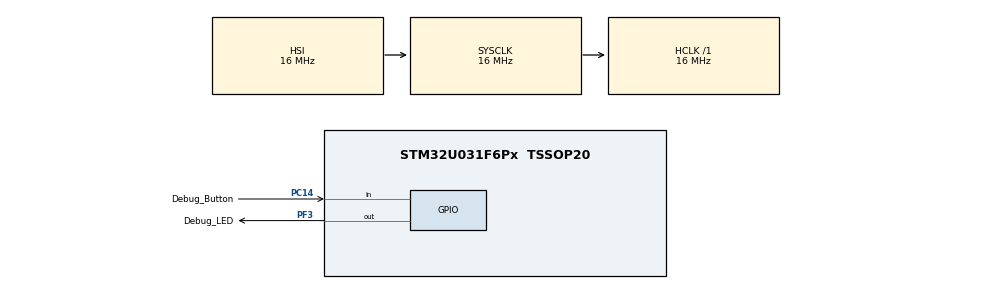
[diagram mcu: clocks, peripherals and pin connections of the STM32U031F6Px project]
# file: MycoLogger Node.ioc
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Mcu.Family=STM32U0
Mcu.Name=STM32U031F6Px
Mcu.Package=TSSOP20
NVIC.PriorityGroup=NVIC_PRIORITYGROUP_2
PA14\ (SWCLK)__PB4__PB5__PB6.StandardMode=true
PA1__PA2.StandardMode=true
PA3__PA4.StandardMode=true
PA5__PA6.StandardMode=true
PA7__PB0.StandardMode=true
PB8__PB9.StandardMode=true
PC14-OSC32_IN.GPIO_Label=Debug_Button
PC14-OSC32_IN.GPIO_PuPd=GPIO_PULLUP
PC14-OSC32_IN.Signal=GPIO_Input
PF3-BOOT0\ (BOOT0).GPIO_Label=Debug_LED
PF3-BOOT0\ (BOOT0).Signal=GPIO_Output
ProjectManager.HeapSize=0x200
ProjectManager.StackSize=0x400
ProjectManager.TargetToolchain=STM32CubeIDE
RCC.AHBFreq_Value=16000000
RCC.CortexFreq_Value=16000000
RCC.HCLKFreq_Value=16000000
RCC.HSE_VALUE=4000000
RCC.HSI48_VALUE=48000000
RCC.HSI_VALUE=16000000
RCC.LSE_VALUE=32768
RCC.MSI_VALUE=4000000
RCC.SYSCLKFreq_VALUE=16000000
RCC.VCOOutputFreq_Value=64000000
VP_PWR_VS_SECSignals.Mode=Security/Privilege
board=custom

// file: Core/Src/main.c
/* USER CODE BEGIN Header */
/**
  ******************************************************************************
  * @file           : main.c
  * @brief          : Main program body
  ******************************************************************************
  * @attention
  *
  * Copyright (c) 2026 STMicroelectronics.
  * All rights reserved.
  *
  * This software is licensed under terms that can be found in the LICENSE file
  * in the root directory of this software component.
  * If no LICENSE file comes with this software, it is provided AS-IS.
  *
  ******************************************************************************
  */
/* USER CODE END Header */
#include "main.h"

/* USER CODE BEGIN Includes */

#include "sx1262_tx.h"
#include "scd41.h"
#include "node_config.h"
#include "battery_adc.h"

/* USER CODE END Includes */

/* USER CODE BEGIN PD */

#define BOOT_BLINK_TIME_MS          100U
#define DEFAULT_REPORT_INTERVAL_MS 60000U
#define DEFAULT_DOWNLINK_WINDOW_MS  1500U
#define BUTTON_DEBOUNCE_TIME_MS       30U
#define NODE_ID_BLINK_ON_TIME_MS      90U
#define NODE_ID_BLINK_OFF_TIME_MS    110U
#define CONFIG_BLINK_COUNT              6U
#define CONFIG_BLINK_ON_TIME_MS        45U
#define CONFIG_BLINK_OFF_TIME_MS       55U
#define NETWORK_CHECK_DURATION_MS    30000U
#define NETWORK_BLINK_ON_TIME_MS       100U
#define NETWORK_BLINK_OFF_TIME_MS      100U
#define NETWORK_BLINK_PAUSE_MS        1000U
#define NETWORK_FAIL_BLINK_COUNT         5U
#define RADIO_RETRY_INTERVAL_MS     5000U
#define RADIO_ERROR_PATTERN_MS      2000U
#define SENSOR_PACKET_SIZE            51U
#define CONFIG_PACKET_SIZE            26U
#define CONFIG_ACK_PACKET_SIZE        27U
#define TEST_PACKET_VERSION            1U
#define TEST_PACKET_SENSOR_READING     2U
#define TEST_PACKET_LINK_CHECK         3U
#define TEST_PACKET_SET_CONFIG      0x80U
#define TEST_PACKET_CONFIG_ACK      0x81U
#define TEST_PACKET_LINK_ACK        0x82U
#define LINK_ACK_PACKET_SIZE           14U
#define LINK_CHECK_PACKET_SIZE         14U
#define DEFAULT_NODE_ID                0U
#define FIRMWARE_VERSION_MAJOR         0U
#define FIRMWARE_VERSION_MINOR         8U
#define FIRMWARE_VERSION_PATCH         6U
#define IWDG_KEY_ENABLE             0xCCCCU
#define IWDG_KEY_WRITE_ACCESS       0x5555U
#define IWDG_KEY_REFRESH            0xAAAAU
#define IWDG_PRESCALER_DIV64              4U
#define IWDG_RELOAD_8_SECONDS          3999U
#define IWDG_WINDOW_DISABLED           4095U
#define IWDG_UPDATE_TIMEOUT_MS           10U
#define IWDG_REFRESH_INTERVAL_MS       1000U
#define LPTIM_LSI_HZ                  32000U
#define LPTIM_STOP_PRESCALER             5U /* /32, therefore 1 kHz. */
#define LPTIM_TICKS_PER_SECOND        1000U
#define LPTIM_MAX_SLEEP_SECONDS         65U
#define RESET_CAUSE_FLAGS (RCC_CSR_OBLRSTF | RCC_CSR_PINRSTF | \
                           RCC_CSR_PWRRSTF | RCC_CSR_SFTRSTF | \
                           RCC_CSR_IWDGRSTF | RCC_CSR_WWDGRSTF | \
                           RCC_CSR_LPWRRSTF)

/* USER CODE END PD */

/* USER CODE BEGIN PV */

/* Retained for ST-LINK inspection and future over-the-air diagnostics. */
volatile uint32_t g_boot_reset_flags = 0U;
volatile bool g_stop_timer_wake = false;
volatile bool g_debug_button_wake = false;

/* USER CODE END PV */

void SystemClock_Config(void);
static void MX_GPIO_Init(void);

/* USER CODE BEGIN 0 */

static void BlinkDebugLedAtBoot(void)
{
  for (uint8_t blink = 0; blink < 3U; blink++)
  {
    HAL_GPIO_WritePin(Debug_LED_GPIO_Port, Debug_LED_Pin, GPIO_PIN_SET);
    HAL_Delay(BOOT_BLINK_TIME_MS);

    HAL_GPIO_WritePin(Debug_LED_GPIO_Port, Debug_LED_Pin, GPIO_PIN_RESET);
    HAL_Delay(BOOT_BLINK_TIME_MS);
  }
}

static bool IndependentWatchdog_Start(void)
{
  uint32_t started;

  /* Keep source-level debugging usable; deployed operation is unaffected. */
  DBGMCU->APBFZ1 |= DBGMCU_APBFZ1_DBG_IWDG_STOP;

  /* Start the LSI-clocked watchdog, then program an approximately 8 s period. */
  IWDG->KR = IWDG_KEY_ENABLE;
  IWDG->KR = IWDG_KEY_WRITE_ACCESS;
  IWDG->PR = IWDG_PRESCALER_DIV64;
  IWDG->RLR = IWDG_RELOAD_8_SECONDS;
  IWDG->WINR = IWDG_WINDOW_DISABLED;

  started = HAL_GetTick();
  while ((IWDG->SR & (IWDG_SR_PVU | IWDG_SR_RVU | IWDG_SR_WVU)) != 0U)
  {
    if ((HAL_GetTick() - started) >= IWDG_UPDATE_TIMEOUT_MS)
    {
      return false;
    }
  }

  IWDG->KR = IWDG_KEY_REFRESH;
  return true;
}

static bool Stop2_IsWatchdogSafe(void)
{
  /* A zero IWDG_STOP option freezes the watchdog during Stop mode. */
  return (FLASH->OPTR & FLASH_OPTR_IWDG_STOP) == 0U;
}

static bool Stop2_Init(void)
{
  uint32_t started = HAL_GetTick();

  __HAL_RCC_LSI_ENABLE();
  while ((RCC->CSR & RCC_CSR_LSIRDY) == 0U)
  {
    if ((HAL_GetTick() - started) >= IWDG_UPDATE_TIMEOUT_MS)
    {
      return false;
    }
  }

  __HAL_RCC_LPTIM1_CLK_ENABLE();
  __HAL_RCC_LPTIM1_CONFIG(RCC_LPTIM1CLKSOURCE_LSI);
  LPTIM1->CR = 0U;
  LPTIM1->CFGR = (LPTIM_STOP_PRESCALER << LPTIM_CFGR_PRESC_Pos);
  LPTIM1->ICR = 0x7FU;
  LPTIM1->DIER = LPTIM_DIER_ARRMIE;
  HAL_NVIC_SetPriority(TIM6_DAC_LPTIM1_IRQn, 2U, 0U);
  HAL_NVIC_EnableIRQ(TIM6_DAC_LPTIM1_IRQn);
  return true;
}

static void Stop2_ArmTimer(uint32_t sleep_seconds)
{
  uint32_t ticks = sleep_seconds * LPTIM_TICKS_PER_SECOND;

  if (ticks == 0U)
  {
    ticks = 1U;
  }
  if (ticks > UINT16_MAX)
  {
    ticks = UINT16_MAX;
  }

  LPTIM1->CR = 0U;
  LPTIM1->ICR = 0x7FU;
  LPTIM1->CR = LPTIM_CR_ENABLE;
  LPTIM1->ARR = ticks - 1U;
  while ((LPTIM1->ISR & LPTIM_ISR_ARROK) == 0U)
  {
  }
  LPTIM1->ICR = LPTIM_ICR_ARROKCF;
  LPTIM1->CR |= LPTIM_CR_SNGSTRT;
}

static void Stop2_Enter(uint32_t sleep_seconds)
{
  Stop2_ArmTimer(sleep_seconds);
  g_stop_timer_wake = false;
  EXTI->RPR1 = EXTI_RPR1_RPIF14;
  EXTI->FPR1 = EXTI_FPR1_FPIF14;
  HAL_SuspendTick();
  MODIFY_REG(PWR->CR1, PWR_CR1_LPMS, PWR_CR1_LPMS_1);
  SET_BIT(SCB->SCR, SCB_SCR_SLEEPDEEP_Msk);
  __DSB();
  __ISB();
  __WFI();
  CLEAR_BIT(SCB->SCR, SCB_SCR_SLEEPDEEP_Msk);
  /* A button wake can arrive before the timer. Do not let the old one-shot
     expire while a sensor/radio state machine is now running. */
  LPTIM1->CR = 0U;
  SystemClock_Config();
  HAL_ResumeTick();
}

void LPTIM1_StopWake_IRQHandler(void)
{
  if ((LPTIM1->ISR & LPTIM_ISR_ARRM) != 0U)
  {
    LPTIM1->ICR = LPTIM_ICR_ARRMCF;
    g_stop_timer_wake = true;
  }
}

void DebugButton_StopWake_IRQHandler(void)
{
  if ((EXTI->FPR1 & EXTI_FPR1_FPIF14) != 0U)
  {
    EXTI->FPR1 = EXTI_FPR1_FPIF14;
    g_debug_button_wake = true;
  }
}

static void IndependentWatchdog_Refresh(void)
{
  IWDG->KR = IWDG_KEY_REFRESH;
}

static void IncrementFailureCounter(uint16_t *counter)
{
  if ((counter != NULL) && (*counter != UINT16_MAX))
  {
    (*counter)++;
  }
}

static bool NetworkCheckIsStillAllowed(uint32_t now,
                                       uint32_t started)
{
  return (now - started) < NETWORK_CHECK_DURATION_MS;
}

static bool NetworkIndicatorIsOn(uint32_t now, uint32_t started)
{
  const uint32_t cycle = NETWORK_BLINK_ON_TIME_MS +
                         NETWORK_BLINK_OFF_TIME_MS +
                         NETWORK_BLINK_ON_TIME_MS +
                         NETWORK_BLINK_PAUSE_MS;
  uint32_t phase = (now - started) % cycle;

  return (phase < NETWORK_BLINK_ON_TIME_MS) ||
         ((phase >= (NETWORK_BLINK_ON_TIME_MS + NETWORK_BLINK_OFF_TIME_MS)) &&
          (phase < (NETWORK_BLINK_ON_TIME_MS + NETWORK_BLINK_OFF_TIME_MS +
                    NETWORK_BLINK_ON_TIME_MS)));
}

static void WriteUint32BigEndian(uint8_t *destination, uint32_t value)
{
  destination[0] = (uint8_t)(value >> 24);
  destination[1] = (uint8_t)(value >> 16);
  destination[2] = (uint8_t)(value >> 8);
  destination[3] = (uint8_t)value;
}

static void WriteUint16BigEndian(uint8_t *destination, uint16_t value)
{
  destination[0] = (uint8_t)(value >> 8);
  destination[1] = (uint8_t)value;
}

static uint32_t ReadUint32BigEndian(const uint8_t *source)
{
  return ((uint32_t)source[0] << 24) |
         ((uint32_t)source[1] << 16) |
         ((uint32_t)source[2] << 8) |
         (uint32_t)source[3];
}

static void BuildSensorPacket(uint8_t *packet,
                              const MycoNodeConfig *config,
                              uint32_t sequence,
                              bool buttonPressed,
                              bool networkCheckRequested,
                              bool sensorValid,
                              bool batteryValid,
                              uint16_t batteryMillivolts,
                              const SCD41Measurement *measurement,
                              SCD41Error sensorError,
                              uint16_t sensorFailureCount,
                              uint16_t radioFailureCount)
{
  packet[0] = 'M';
  packet[1] = 'Y';
  packet[2] = 'C';
  packet[3] = 'O';
  packet[4] = TEST_PACKET_VERSION;
  packet[5] = TEST_PACKET_SENSOR_READING;
  WriteUint32BigEndian(&packet[6], config->node_id);
  WriteUint32BigEndian(&packet[10], sequence);
  WriteUint32BigEndian(&packet[14], HAL_GetTick() / 1000U);
  packet[18] = (buttonPressed ? 0x01U : 0x00U) |
               (sensorValid ? 0x02U : 0x00U) |
               (batteryValid ? 0x04U : 0x00U) |
               (networkCheckRequested ? 0x08U : 0x00U);
  WriteUint16BigEndian(&packet[19],
                       sensorValid ? measurement->co2_ppm : 0U);
  WriteUint16BigEndian(
      &packet[21],
      sensorValid ? (uint16_t)measurement->temperature_centi_c : 0U);
  WriteUint16BigEndian(
      &packet[23],
      sensorValid ? measurement->humidity_centi_percent : 0U);
  packet[25] = (uint8_t)sensorError;
  WriteUint32BigEndian(&packet[26], config->revision);
  WriteUint32BigEndian(&packet[30], config->report_interval_ms / 1000U);
  WriteUint16BigEndian(&packet[34],
                       batteryValid ? batteryMillivolts : 0U);
  /* A compact semantic version is included in every measurement. Repeating
     three bytes makes version discovery self-healing after server restarts or
     database restores without materially affecting LoRa airtime. */
  packet[36] = FIRMWARE_VERSION_MAJOR;
  packet[37] = FIRMWARE_VERSION_MINOR;
  packet[38] = FIRMWARE_VERSION_PATCH;
  /* These counters reset at boot and describe recoverable failures observed
     since this boot.  The reset flags identify why the current boot began. */
  WriteUint32BigEndian(&packet[39], g_boot_reset_flags);
  WriteUint16BigEndian(&packet[43], sensorFailureCount);
  WriteUint16BigEndian(&packet[45], radioFailureCount);
  WriteUint32BigEndian(&packet[47], config->downlink_window_ms);
}

static bool ApplyConfigPacket(const SX1262RxPacket *packet,
                              MycoNodeConfig *config,
                              uint32_t *transactionId,
                              uint8_t *status)
{
  uint32_t targetNodeId;
  uint32_t revision;
  uint32_t reportIntervalS;

  if ((packet == NULL) || (config == NULL) ||
      (transactionId == NULL) || (status == NULL) ||
      (packet->length != CONFIG_PACKET_SIZE) ||
      (packet->payload[0] != 'M') ||
      (packet->payload[1] != 'Y') ||
      (packet->payload[2] != 'C') ||
      (packet->payload[3] != 'O') ||
      (packet->payload[4] != TEST_PACKET_VERSION) ||
      (packet->payload[5] != TEST_PACKET_SET_CONFIG))
  {
    return false;
  }

  targetNodeId = ReadUint32BigEndian(&packet->payload[6]);
  *transactionId = ReadUint32BigEndian(&packet->payload[10]);
  revision = ReadUint32BigEndian(&packet->payload[14]);
  reportIntervalS = ReadUint32BigEndian(&packet->payload[18]);
  uint32_t downlinkWindowMs = ReadUint32BigEndian(&packet->payload[22]);

  return NodeConfig_Apply(config,
                          targetNodeId,
                          *transactionId,
                          revision,
                          reportIntervalS,
                          downlinkWindowMs,
                          status);
}

static void BuildConfigAckPacket(uint8_t *packet,
                                 const MycoNodeConfig *config,
                                 uint32_t transactionId,
                                 uint8_t status)
{
  packet[0] = 'M';
  packet[1] = 'Y';
  packet[2] = 'C';
  packet[3] = 'O';
  packet[4] = TEST_PACKET_VERSION;
  packet[5] = TEST_PACKET_CONFIG_ACK;
  WriteUint32BigEndian(&packet[6], config->node_id);
  WriteUint32BigEndian(&packet[10], transactionId);
  WriteUint32BigEndian(&packet[14], config->revision);
  packet[18] = status;
  WriteUint32BigEndian(&packet[19], config->report_interval_ms / 1000U);
  WriteUint32BigEndian(&packet[23], config->downlink_window_ms);
}

static bool IsLinkAckPacket(const SX1262RxPacket *packet,
                            const MycoNodeConfig *config,
                            uint32_t expectedSequence)
{
  return (packet != NULL) && (config != NULL) &&
         (packet->length == LINK_ACK_PACKET_SIZE) &&
         (packet->payload[0] == 'M') &&
         (packet->payload[1] == 'Y') &&
         (packet->payload[2] == 'C') &&
         (packet->payload[3] == 'O') &&
         (packet->payload[4] == TEST_PACKET_VERSION) &&
         (packet->payload[5] == TEST_PACKET_LINK_ACK) &&
         (ReadUint32BigEndian(&packet->payload[6]) == config->node_id) &&
         (ReadUint32BigEndian(&packet->payload[10]) == expectedSequence);
}

static void BuildLinkCheckPacket(uint8_t *packet,
                                 const MycoNodeConfig *config,
                                 uint32_t checkSequence)
{
  packet[0] = 'M';
  packet[1] = 'Y';
  packet[2] = 'C';
  packet[3] = 'O';
  packet[4] = TEST_PACKET_VERSION;
  packet[5] = TEST_PACKET_LINK_CHECK;
  WriteUint32BigEndian(&packet[6], config->node_id);
  WriteUint32BigEndian(&packet[10], checkSequence);
}

/* USER CODE END 0 */

int main(void)
{

  /* MCU Configuration--------------------------------------------------------*/

  /* Reset of all peripherals, Initializes the Flash interface and the Systick. */
  HAL_Init();

  /* USER CODE BEGIN Init */

  g_boot_reset_flags = RCC->CSR & RESET_CAUSE_FLAGS;
  RCC->CSR |= RCC_CSR_RMVF;

  /* USER CODE END Init */

  /* Configure the system clock */
  SystemClock_Config();

  /* Initialize all configured peripherals */
  MX_GPIO_Init();
  /* USER CODE BEGIN 2 */

  if (!IndependentWatchdog_Start())
  {
    Error_Handler();
  }

  BlinkDebugLedAtBoot();
  SX1262_TX_BusInit();
  SCD41_BusInit();
  BatteryADC_InitPin();

  MycoNodeConfig nodeConfig;
  NodeConfig_Load(&nodeConfig,
                  DEFAULT_NODE_ID,
                  DEFAULT_REPORT_INTERVAL_MS,
                  DEFAULT_DOWNLINK_WINDOW_MS);
  bool provisioningConfirmation =
      NodeConfig_ConsumeProvisioningMarker(&nodeConfig);

  /* Node zero is deliberately silent until an ST-LINK provisioner writes a
     valid identity into the reserved configuration flash page. */
  if (nodeConfig.node_id == 0U)
  {
    while (1)
    {
      for (uint32_t flash = 0U; flash < 4U; flash++)
      {
        HAL_GPIO_WritePin(Debug_LED_GPIO_Port,
                          Debug_LED_Pin,
                          GPIO_PIN_SET);
        HAL_Delay(90U);
        HAL_GPIO_WritePin(Debug_LED_GPIO_Port,
                          Debug_LED_Pin,
                          GPIO_PIN_RESET);
        HAL_Delay(110U);
      }
      IndependentWatchdog_Refresh();
      HAL_Delay(1800U);
    }
  }

  uint8_t radioStatus = 0U;
  bool radioReady =
      SX1262_TX_Init(&radioStatus) == SX1262_TX_STATUS_OK;
  bool sensorCycleFailed = false;
  uint16_t sensorFailureCount = 0U;
  uint16_t radioFailureCount = 0U;
  bool sensorMeasurementValid = false;
  bool sensorPacketPending = false;
  bool sensorTransmitActive = false;
  bool downlinkReceiveActive = false;
  bool configAckTransmitActive = false;
  bool networkLinkPacketPending = radioReady;
  bool networkLinkTransmitActive = false;
  bool networkConfirmationPending = true;
  bool networkStartupCheckActive = radioReady;
  bool stop2Ready = Stop2_IsWatchdogSafe() && Stop2_Init();
  uint32_t networkCheckSequence = 0U;
  uint32_t networkCheckStartedTick = HAL_GetTick();
  SCD41Measurement sensorMeasurement = {0};
  uint32_t lastRadioInitTick = HAL_GetTick();
  uint32_t lastSensorCycleTick = HAL_GetTick();
  uint32_t stop2ElapsedMs = 0U;
  uint32_t stop2ArmedMs = 0U;
  uint32_t ledSequenceTick = HAL_GetTick();
  uint32_t ledSequenceBlinksRemaining =
      provisioningConfirmation ? CONFIG_BLINK_COUNT : 0U;
  uint32_t ledSequenceOnTimeMs = CONFIG_BLINK_ON_TIME_MS;
  uint32_t ledSequenceOffTimeMs = CONFIG_BLINK_OFF_TIME_MS;
  bool ledSequenceActive = provisioningConfirmation;
  bool ledSequenceLedOn = provisioningConfirmation;
  uint32_t transmitSequence = 0U;
  uint8_t sensorPacket[SENSOR_PACKET_SIZE];
  uint8_t linkCheckPacket[LINK_CHECK_PACKET_SIZE];
  uint8_t configAckPacket[CONFIG_ACK_PACKET_SIZE];
  SX1262RxPacket downlinkPacket;
  uint32_t configTransactionId = 0U;
  uint8_t configStatus = 0U;
  uint16_t batteryMillivolts = 0U;
  GPIO_PinState rawButtonState =
      HAL_GPIO_ReadPin(Debug_Button_GPIO_Port, Debug_Button_Pin);
  GPIO_PinState previousRawButtonState = rawButtonState;
  GPIO_PinState debouncedButtonState = rawButtonState;
  uint32_t buttonDebounceTick = HAL_GetTick();
  uint32_t lastWatchdogRefreshTick = HAL_GetTick();

  /* Take the first sample immediately; subsequent starts are one minute apart. */
  if (SCD41_StartSingleShot() != SCD41_STATUS_OK)
  {
    sensorCycleFailed = true;
    IncrementFailureCounter(&sensorFailureCount);
    sensorPacketPending = true;
  }

  /* USER CODE END 2 */

  /* Infinite loop */
  while (1)
  {

    /* USER CODE BEGIN 3 */
    uint32_t now = HAL_GetTick();
    if (g_debug_button_wake)
    {
      g_debug_button_wake = false;
      rawButtonState = GPIO_PIN_RESET;
      previousRawButtonState = GPIO_PIN_RESET;
      buttonDebounceTick = now - BUTTON_DEBOUNCE_TIME_MS;
    }
    else
    {
      rawButtonState = HAL_GPIO_ReadPin(Debug_Button_GPIO_Port,
                                        Debug_Button_Pin);
    }
    if (rawButtonState != previousRawButtonState)
    {
      previousRawButtonState = rawButtonState;
      buttonDebounceTick = now;
    }

    if (((now - buttonDebounceTick) >= BUTTON_DEBOUNCE_TIME_MS) &&
        (rawButtonState != debouncedButtonState))
    {
      debouncedButtonState = rawButtonState;
      if (debouncedButtonState == GPIO_PIN_RESET)
      {
        /* Identify this physical transmitter without blocking sensing/radio. */
        ledSequenceBlinksRemaining = nodeConfig.node_id;
        ledSequenceOnTimeMs = NODE_ID_BLINK_ON_TIME_MS;
        ledSequenceOffTimeMs = NODE_ID_BLINK_OFF_TIME_MS;
        ledSequenceActive = ledSequenceBlinksRemaining > 0U;
        ledSequenceLedOn = ledSequenceActive;
        ledSequenceTick = now;

        if (!SCD41_IsActive())
        {
          /* A press always requests a new sensor conversion before transmit. */
          stop2ElapsedMs = 0U;
          lastSensorCycleTick = now;
          sensorMeasurementValid = false;
          if (SCD41_StartSingleShot() != SCD41_STATUS_OK)
          {
            sensorCycleFailed = true;
            IncrementFailureCounter(&sensorFailureCount);
            sensorPacketPending = true;
          }
        }
      }
    }

    bool buttonPressed = debouncedButtonState == GPIO_PIN_RESET;

    if (g_stop_timer_wake)
    {
      g_stop_timer_wake = false;
      stop2ElapsedMs += stop2ArmedMs;
      stop2ArmedMs = 0U;
    }

    if (SCD41_IsActive())
    {
      SCD41Event sensorEvent = SCD41_Poll(&sensorMeasurement);
      if (sensorEvent == SCD41_EVENT_MEASUREMENT)
      {
        sensorMeasurementValid = true;
        sensorCycleFailed = false;
        sensorPacketPending = true;
      }
      else if ((sensorEvent == SCD41_EVENT_BUS_ERROR) ||
               (sensorEvent == SCD41_EVENT_CRC_ERROR))
      {
        sensorMeasurementValid = false;
        sensorCycleFailed = true;
        IncrementFailureCounter(&sensorFailureCount);
        sensorPacketPending = true;
      }
    }
    else if (((now - lastSensorCycleTick) + stop2ElapsedMs) >=
             nodeConfig.report_interval_ms)
    {
      stop2ElapsedMs = 0U;
      HAL_GPIO_WritePin(Sensor_Power_GPIO_Port,
                        Sensor_Power_Pin,
                        GPIO_PIN_RESET);
      lastSensorCycleTick = now;
      sensorMeasurementValid = false;
      if (SCD41_StartSingleShot() != SCD41_STATUS_OK)
      {
        sensorCycleFailed = true;
        IncrementFailureCounter(&sensorFailureCount);
        sensorPacketPending = true;
      }
    }

    if (!radioReady &&
        ((now - lastRadioInitTick) >= RADIO_RETRY_INTERVAL_MS))
    {
      lastRadioInitTick = now;
      radioReady =
          SX1262_TX_Init(&radioStatus) == SX1262_TX_STATUS_OK;
      if (!radioReady)
      {
        IncrementFailureCounter(&radioFailureCount);
      }
      if (radioReady && networkConfirmationPending &&
          NetworkCheckIsStillAllowed(now, networkCheckStartedTick))
      {
        networkStartupCheckActive = true;
        networkLinkPacketPending = true;
      }
    }

    if (radioReady && networkLinkPacketPending &&
        !SX1262_TX_IsActive())
    {
      networkCheckSequence++;
      BuildLinkCheckPacket(linkCheckPacket,
                           &nodeConfig,
                           networkCheckSequence);
      if (SX1262_TX_Start(linkCheckPacket, sizeof(linkCheckPacket)) ==
          SX1262_TX_STATUS_OK)
      {
        networkLinkPacketPending = false;
        networkLinkTransmitActive = true;
      }
      else
      {
        IncrementFailureCounter(&radioFailureCount);
        networkStartupCheckActive = false;
        radioReady = false;
        lastRadioInitTick = now;
      }
    }
    else if (radioReady && sensorPacketPending && !SX1262_TX_IsActive())
    {
      uint32_t nextSequence = transmitSequence + 1U;
      bool batteryValid =
          BatteryADC_ReadMillivolts(&batteryMillivolts);
      BuildSensorPacket(sensorPacket,
                        &nodeConfig,
                        nextSequence,
                        buttonPressed,
                        networkConfirmationPending,
                        sensorMeasurementValid,
                        batteryValid,
                        batteryMillivolts,
                        &sensorMeasurement,
                        SCD41_GetLastError(),
                        sensorFailureCount,
                        radioFailureCount);

      if (SX1262_TX_Start(sensorPacket, sizeof(sensorPacket)) ==
          SX1262_TX_STATUS_OK)
      {
        transmitSequence = nextSequence;
        if (networkConfirmationPending && !networkStartupCheckActive)
        {
          /* Later reports continue checking after a bounded boot failure. */
          networkCheckSequence = nextSequence;
        }
        sensorPacketPending = false;
        sensorTransmitActive = true;
      }
      else
      {
        IncrementFailureCounter(&radioFailureCount);
        networkStartupCheckActive = false;
        radioReady = false;
        lastRadioInitTick = now;
      }
    }

    if (radioReady && networkLinkTransmitActive)
    {
      SX1262TxEvent event = SX1262_TX_Poll();
      if (event == SX1262_TX_EVENT_DONE)
      {
        networkLinkTransmitActive = false;
        if (SX1262_TX_StartReceive(nodeConfig.downlink_window_ms) ==
            SX1262_TX_STATUS_OK)
        {
          downlinkReceiveActive = true;
        }
        else
        {
          IncrementFailureCounter(&radioFailureCount);
          networkStartupCheckActive = false;
          radioReady = false;
          lastRadioInitTick = now;
        }
      }
      else if ((event == SX1262_TX_EVENT_TIMEOUT) ||
               (event == SX1262_TX_EVENT_BUS_ERROR))
      {
        IncrementFailureCounter(&radioFailureCount);
        networkLinkTransmitActive = false;
        networkStartupCheckActive = false;
        radioReady = false;
        lastRadioInitTick = now;
      }
    }
    else if (radioReady && sensorTransmitActive)
    {
      SX1262TxEvent event = SX1262_TX_Poll();
      if (event == SX1262_TX_EVENT_DONE)
      {
        sensorTransmitActive = false;
        if (SX1262_TX_StartReceive(nodeConfig.downlink_window_ms) ==
            SX1262_TX_STATUS_OK)
        {
          downlinkReceiveActive = true;
        }
        else
        {
          IncrementFailureCounter(&radioFailureCount);
          networkStartupCheckActive = false;
          radioReady = false;
          lastRadioInitTick = now;
        }
      }
      else if ((event == SX1262_TX_EVENT_TIMEOUT) ||
               (event == SX1262_TX_EVENT_BUS_ERROR))
      {
        IncrementFailureCounter(&radioFailureCount);
        sensorTransmitActive = false;
        networkStartupCheckActive = false;
        radioReady = false;
        lastRadioInitTick = now;
      }
    }
    else if (radioReady && downlinkReceiveActive)
    {
      SX1262RxEvent event = SX1262_TX_PollReceive(&downlinkPacket);
      if (event == SX1262_RX_EVENT_PACKET)
      {
        uint32_t previousConfigRevision = nodeConfig.revision;
        downlinkReceiveActive = false;
        bool configPacketAccepted =
            ApplyConfigPacket(&downlinkPacket,
                              &nodeConfig,
                              &configTransactionId,
                              &configStatus);
        bool linkAcknowledged =
            IsLinkAckPacket(&downlinkPacket,
                            &nodeConfig,
                            networkCheckSequence);

        if (configPacketAccepted || linkAcknowledged)
        {
          bool wasStartupCheck = networkStartupCheckActive;
          networkConfirmationPending = false;
          networkStartupCheckActive = false;

          if (linkAcknowledged && !wasStartupCheck)
          {
            /* Confirm recovery if the receiver was unavailable at startup. */
            ledSequenceBlinksRemaining = CONFIG_BLINK_COUNT;
            ledSequenceOnTimeMs = CONFIG_BLINK_ON_TIME_MS;
            ledSequenceOffTimeMs = CONFIG_BLINK_OFF_TIME_MS;
            ledSequenceActive = true;
            ledSequenceLedOn = true;
            ledSequenceTick = now;
          }
        }
        else if (networkStartupCheckActive)
        {
          /* An unrelated downlink is not proof that this node was reached. */
          if (NetworkCheckIsStillAllowed(now, networkCheckStartedTick))
          {
            networkLinkPacketPending = true;
          }
          else
          {
            networkStartupCheckActive = false;
            ledSequenceBlinksRemaining = NETWORK_FAIL_BLINK_COUNT;
            ledSequenceOnTimeMs = NETWORK_BLINK_ON_TIME_MS;
            ledSequenceOffTimeMs = NETWORK_BLINK_OFF_TIME_MS;
            ledSequenceActive = true;
            ledSequenceLedOn = true;
            ledSequenceTick = now;
          }
        }

        if (configPacketAccepted)
        {
          if ((configStatus == NODE_CONFIG_STATUS_APPLIED) &&
              (nodeConfig.revision != previousConfigRevision))
          {
            /* A short flurry confirms a newly accepted receiver command. */
            ledSequenceBlinksRemaining = CONFIG_BLINK_COUNT;
            ledSequenceOnTimeMs = CONFIG_BLINK_ON_TIME_MS;
            ledSequenceOffTimeMs = CONFIG_BLINK_OFF_TIME_MS;
            ledSequenceActive = true;
            ledSequenceLedOn = true;
            ledSequenceTick = now;
          }
          BuildConfigAckPacket(configAckPacket,
                               &nodeConfig,
                               configTransactionId,
                               configStatus);
          /* Give the receiver time to return from TX to continuous RX. */
          HAL_Delay(30U);
          if (SX1262_TX_Start(configAckPacket,
                              sizeof(configAckPacket)) ==
              SX1262_TX_STATUS_OK)
          {
            configAckTransmitActive = true;
          }
          else
          {
            IncrementFailureCounter(&radioFailureCount);
            radioReady = false;
            lastRadioInitTick = now;
          }
        }
      }
      else if ((event == SX1262_RX_EVENT_TIMEOUT) ||
               (event == SX1262_RX_EVENT_CRC_ERROR) ||
               (event == SX1262_RX_EVENT_HEADER_ERROR))
      {
        downlinkReceiveActive = false;
        if (networkStartupCheckActive)
        {
          if (NetworkCheckIsStillAllowed(now, networkCheckStartedTick))
          {
            networkLinkPacketPending = true;
          }
          else
          {
            networkStartupCheckActive = false;
            ledSequenceBlinksRemaining = NETWORK_FAIL_BLINK_COUNT;
            ledSequenceOnTimeMs = NETWORK_BLINK_ON_TIME_MS;
            ledSequenceOffTimeMs = NETWORK_BLINK_OFF_TIME_MS;
            ledSequenceActive = true;
            ledSequenceLedOn = true;
            ledSequenceTick = now;
          }
        }
      }
      else if (event == SX1262_RX_EVENT_BUS_ERROR)
      {
        IncrementFailureCounter(&radioFailureCount);
        downlinkReceiveActive = false;
        networkStartupCheckActive = false;
        radioReady = false;
        lastRadioInitTick = now;
      }
    }
    else if (radioReady && configAckTransmitActive)
    {
      SX1262TxEvent event = SX1262_TX_Poll();
      if (event == SX1262_TX_EVENT_DONE)
      {
        configAckTransmitActive = false;
      }
      else if ((event == SX1262_TX_EVENT_TIMEOUT) ||
               (event == SX1262_TX_EVENT_BUS_ERROR))
      {
        IncrementFailureCounter(&radioFailureCount);
        configAckTransmitActive = false;
        radioReady = false;
        lastRadioInitTick = now;
      }
    }

    /* The SX1262 is otherwise left in standby between reports. Warm sleep
       retains its radio configuration and is exited automatically by Start(). */
    if (radioReady && !networkLinkPacketPending && !sensorPacketPending &&
        !networkLinkTransmitActive && !sensorTransmitActive &&
        !downlinkReceiveActive && !configAckTransmitActive &&
        !SX1262_TX_IsActive() &&
        (SX1262_TX_Sleep() != SX1262_TX_STATUS_OK))
    {
      IncrementFailureCounter(&radioFailureCount);
      radioReady = false;
      lastRadioInitTick = now;
    }

    if (ledSequenceActive)
    {
      uint32_t phaseDuration = ledSequenceLedOn
          ? ledSequenceOnTimeMs
          : ledSequenceOffTimeMs;
      if ((now - ledSequenceTick) >= phaseDuration)
      {
        ledSequenceTick = now;
        if (ledSequenceLedOn)
        {
          ledSequenceLedOn = false;
          ledSequenceBlinksRemaining--;
          if (ledSequenceBlinksRemaining == 0U)
          {
            ledSequenceActive = false;
          }
        }
        else
        {
          ledSequenceLedOn = true;
        }
      }
    }

    if (ledSequenceActive)
    {
      HAL_GPIO_WritePin(Debug_LED_GPIO_Port,
                        Debug_LED_Pin,
                        ledSequenceLedOn ? GPIO_PIN_SET : GPIO_PIN_RESET);
    }
    else if (networkStartupCheckActive)
    {
      HAL_GPIO_WritePin(Debug_LED_GPIO_Port,
                        Debug_LED_Pin,
                        NetworkIndicatorIsOn(now, networkCheckStartedTick)
                            ? GPIO_PIN_SET
                            : GPIO_PIN_RESET);
    }
    else if (radioReady && sensorCycleFailed &&
             (((now % RADIO_ERROR_PATTERN_MS) < 100U) ||
              (((now % RADIO_ERROR_PATTERN_MS) >= 200U) &&
               ((now % RADIO_ERROR_PATTERN_MS) < 300U)) ||
              (((now % RADIO_ERROR_PATTERN_MS) >= 400U) &&
               ((now % RADIO_ERROR_PATTERN_MS) < 500U))))
    {
      /* Three short flashes mean the SCD41 did not initialize/read. */
      HAL_GPIO_WritePin(Debug_LED_GPIO_Port, Debug_LED_Pin, GPIO_PIN_SET);
    }
    else if (!radioReady &&
             (((now % RADIO_ERROR_PATTERN_MS) < 100U) ||
              (((now % RADIO_ERROR_PATTERN_MS) >= 200U) &&
               ((now % RADIO_ERROR_PATTERN_MS) < 300U))))
    {
      /* Two short flashes mean radio initialization/transmission failed. */
      HAL_GPIO_WritePin(Debug_LED_GPIO_Port, Debug_LED_Pin, GPIO_PIN_SET);
    }
    else
    {
      HAL_GPIO_WritePin(Debug_LED_GPIO_Port, Debug_LED_Pin, GPIO_PIN_RESET);
    }

    /* Refresh only after a full state-machine pass completed. A stuck sensor,
       radio, or fault handler therefore cannot keep the watchdog alive. */
    if ((now - lastWatchdogRefreshTick) >= IWDG_REFRESH_INTERVAL_MS)
    {
      IndependentWatchdog_Refresh();
      lastWatchdogRefreshTick = now;
    }

    if (stop2Ready && !SCD41_IsActive() && radioReady &&
        !sensorPacketPending && !sensorTransmitActive &&
        !downlinkReceiveActive && !configAckTransmitActive &&
        !networkLinkPacketPending && !networkLinkTransmitActive &&
        !networkStartupCheckActive && !ledSequenceActive &&
        !sensorCycleFailed && (debouncedButtonState != GPIO_PIN_RESET))
    {
      uint32_t elapsed = (now - lastSensorCycleTick) + stop2ElapsedMs;
      uint32_t remaining = nodeConfig.report_interval_ms - elapsed;
      uint32_t sleep_seconds = (remaining + 999U) / 1000U;
      if (sleep_seconds > LPTIM_MAX_SLEEP_SECONDS)
      {
        sleep_seconds = LPTIM_MAX_SLEEP_SECONDS;
      }
      stop2ArmedMs = sleep_seconds * 1000U;
      Stop2_Enter(sleep_seconds);
    }
    else
    {
      /* Short active waits retain SysTick for state-machine timing. */
      __WFI();
    }
  }
  /* USER CODE END 3 */
}

void SystemClock_Config(void)
{
  RCC_OscInitTypeDef RCC_OscInitStruct = {0};
  RCC_ClkInitTypeDef RCC_ClkInitStruct = {0};

  /** Configure the main internal regulator output voltage
  */
  HAL_PWREx_ControlVoltageScaling(PWR_REGULATOR_VOLTAGE_SCALE2);

  /** Initializes the RCC Oscillators according to the specified parameters
  * in the RCC_OscInitTypeDef structure.
  */
  RCC_OscInitStruct.OscillatorType = RCC_OSCILLATORTYPE_HSI;
  RCC_OscInitStruct.HSIState = RCC_HSI_ON;
  RCC_OscInitStruct.HSICalibrationValue = RCC_HSICALIBRATION_DEFAULT;
  RCC_OscInitStruct.PLL.PLLState = RCC_PLL_NONE;
  if (HAL_RCC_OscConfig(&RCC_OscInitStruct) != HAL_OK)
  {
    Error_Handler();
  }

  /** Initializes the CPU, AHB and APB buses clocks
  */
  RCC_ClkInitStruct.ClockType = RCC_CLOCKTYPE_HCLK|RCC_CLOCKTYPE_SYSCLK
                              |RCC_CLOCKTYPE_PCLK1;
  RCC_ClkInitStruct.SYSCLKSource = RCC_SYSCLKSOURCE_HSI;
  RCC_ClkInitStruct.AHBCLKDivider = RCC_SYSCLK_DIV1;
  RCC_ClkInitStruct.APB1CLKDivider = RCC_HCLK_DIV1;

  if (HAL_RCC_ClockConfig(&RCC_ClkInitStruct, FLASH_LATENCY_1) != HAL_OK)
  {
    Error_Handler();
  }
}

static void MX_GPIO_Init(void)
{
  GPIO_InitTypeDef GPIO_InitStruct = {0};

  /* GPIO Ports Clock Enable */
  __HAL_RCC_GPIOC_CLK_ENABLE();
  __HAL_RCC_GPIOF_CLK_ENABLE();

  /*Configure GPIO pin Output Level */
  HAL_GPIO_WritePin(Debug_LED_GPIO_Port, Debug_LED_Pin, GPIO_PIN_RESET);

  /*Configure GPIO pin : Debug_Button_Pin */
  GPIO_InitStruct.Pin = Debug_Button_Pin;
  GPIO_InitStruct.Mode = GPIO_MODE_IT_FALLING;
  GPIO_InitStruct.Pull = GPIO_PULLUP;
  HAL_GPIO_Init(Debug_Button_GPIO_Port, &GPIO_InitStruct);
  HAL_NVIC_SetPriority(EXTI4_15_IRQn, 1U, 0U);
  HAL_NVIC_EnableIRQ(EXTI4_15_IRQn);

  /*Configure GPIO pin : Debug_LED_Pin */
  GPIO_InitStruct.Pin = Debug_LED_Pin;
  GPIO_InitStruct.Mode = GPIO_MODE_OUTPUT_PP;
  GPIO_InitStruct.Pull = GPIO_NOPULL;
  GPIO_InitStruct.Speed = GPIO_SPEED_FREQ_LOW;
  HAL_GPIO_Init(Debug_LED_GPIO_Port, &GPIO_InitStruct);

}

void Error_Handler(void)
{
  __disable_irq();
  while (1)
  {
  }
}
